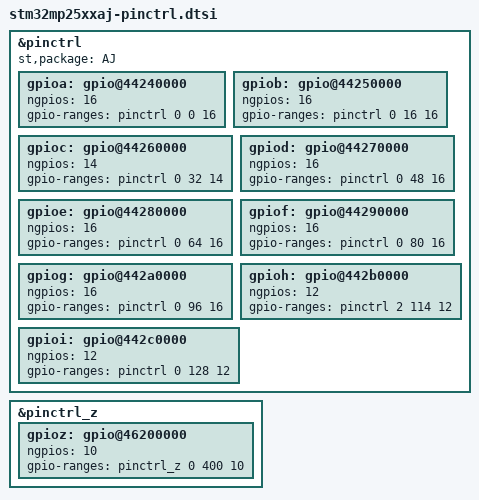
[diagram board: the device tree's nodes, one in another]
// SPDX-License-Identifier: (GPL-2.0-only OR BSD-3-Clause)
/*
 * Copyright (C) STMicroelectronics 2024-2025 - All Rights Reserved
 * Author: Alexandre Torgue <alexandre.torgue@foss.st.com> for STMicroelectronics.
 */

&pinctrl {
	st,package = "AJ";

	gpioa: gpio@44240000 {
		ngpios = <16>;
		gpio-ranges = <&pinctrl 0 0 16>;
		status = "okay";
	};

	gpiob: gpio@44250000 {
		ngpios = <16>;
		gpio-ranges = <&pinctrl 0 16 16>;
		status = "okay";
	};

	gpioc: gpio@44260000 {
		ngpios = <14>;
		gpio-ranges = <&pinctrl 0 32 14>;
		status = "okay";
	};

	gpiod: gpio@44270000 {
		ngpios = <16>;
		gpio-ranges = <&pinctrl 0 48 16>;
		status = "okay";
	};

	gpioe: gpio@44280000 {
		ngpios = <16>;
		gpio-ranges = <&pinctrl 0 64 16>;
		status = "okay";
	};

	gpiof: gpio@44290000 {
		ngpios = <16>;
		gpio-ranges = <&pinctrl 0 80 16>;
		status = "okay";
	};

	gpiog: gpio@442a0000 {
		ngpios = <16>;
		gpio-ranges = <&pinctrl 0 96 16>;
		status = "okay";
	};

	gpioh: gpio@442b0000 {
		ngpios = <12>;
		gpio-ranges = <&pinctrl 2 114 12>;
		status = "okay";
	};

	gpioi: gpio@442c0000 {
		ngpios = <12>;
		gpio-ranges = <&pinctrl 0 128 12>;
		status = "okay";
	};
};

&pinctrl_z {
	gpioz: gpio@46200000 {
		ngpios = <10>;
		gpio-ranges = <&pinctrl_z 0 400 10>;
		status = "okay";
	};
};
